# ODS5010 register map
Vendor: OCS; Series: ODS5010; File version: 1.0
CPU: CM0plus r0p0, little endian, MPU, FPU, 4 interrupt priority bits
Registers are 32-bit, read-write, reset 0x0 unless marked. A register's access mark holds for its fields unless they carry their own. Offsets are from the block's base; [hi:lo] are bit positions; {n}, {i} and the like mark numbered series.

## FLASH — Flash Memory Controller Peripheral
Base 0x40022000; register names take the prefix FLASH_
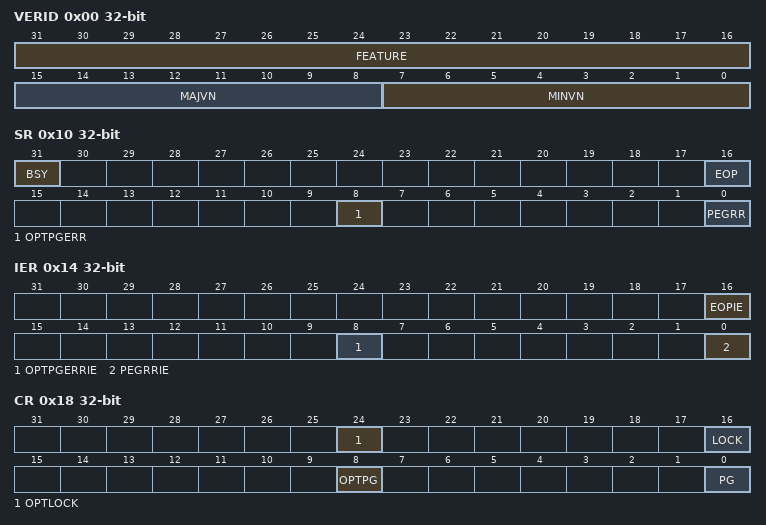
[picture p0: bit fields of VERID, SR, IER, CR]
0x00 VERID ro — Version ID Register (read only)
  [31:16] FEATURE — Feature Identification
  [15:8] MAJVN — Major Version Number
  [7:0] MINVN — Minor Version Number
0x04 ACR — Access Control Register
  [2:0] NWS — Number of Wait States
0x08 KEYR wo — Key Register (write only)
0x0C OPTKEYR wo — Option Key Register (write only)
0x10 SR ro — Status Register
  [31] BSY — Busy
  [16] EOP — End of Operation
  [8] OPTPGERR — Option Program Error
  [0] PEGRR — Program/Erase Global Result Ready
0x14 IER — Interrupt Enable Register
  [16] EOPIE — EOP Interrupt Enable
  [8] OPTPGERRIE — OPTPGERR Interrupt Enable
  [0] PEGRRIE — PEGRR Interrupt Enable
0x18 CR — Control Register
  [24] OPTLOCK — Option Lock
  [16] LOCK — Flash Lock
  [8] OPTPG — Option Program Enable
  [0] PG — Program Enable
0x24 DR ro — Data Register (read only)
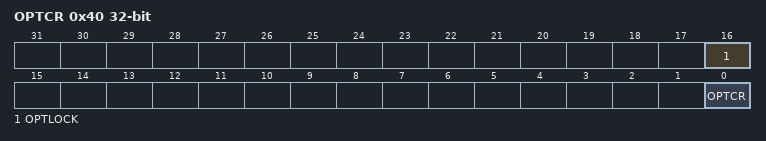
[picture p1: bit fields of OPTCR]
0x40 OPTCR — OTP Control Register
  [16] OPTLOCK — OTP Lock
  [0] OPTCR — OTP Control Bit
0x44 OPTAR — OTP Address Register
  [6:0] OPTAR — OTP Address
0x48 OPTDR — OTP Data Register
0x4C OPTKEY wo — OTP Key Register (write only)

## SYSCFG — System Configuration (SYSCFG) Peripheral
Base 0x40020400; register names take the prefix SYSCFG_
{0x0+4i} UUID{i} ro (i=0..3) — UUID Register {i}
  [31:0] UUID{i} — UUID Value {i}
{0x10+4i} USER{i} ro (i=0..3) — User Configuration Register {i}
  [31:0] USER{i} — User Configuration Value {i}
0x20 TAG ro
  [31:0] TAG — Tag Value
0x24 FLASH_SIZE ro — Flash Memory Size Register
  [31:0] FLASH_SIZE — Flash Memory Size Value
0x28 SRAM_SIZE ro
  [31:0] SRAM_SIZE — SRAM Size Value
0x2C GPIOA ro — Reserved - GPIOA Configuration
  [31:0] GPIOA — Reserved GPIOA Value
0x30 GPIOB ro — Reserved - GPIOB Configuration
  [31:0] GPIOB — Reserved GPIOB Value
0x34 GPIOC ro — Reserved - GPIOC Configuration
  [31:0] GPIOC — Reserved GPIOC Value
0x100 WAKEIR — Wake-Up Interrupt Register
  [31:0] WAKEIR — Wake-Up Interrupt Value
0x104 WAKECR — Wake-Up Control Register
  [31:0] WAKECR — Wake-Up Control Value
0x108 LPTMRTH — Low-Power Timer Threshold Register
  [31:0] LPTMRTH — Low-Power Timer Threshold Value
0x3F8 VERID ro — Version ID Register
  [31:0] VERID — Version ID Value

## MISC — MISC Control Registers (CSA and Temperature Sensor)
Base 0x40007800; register names take the prefix MISC_
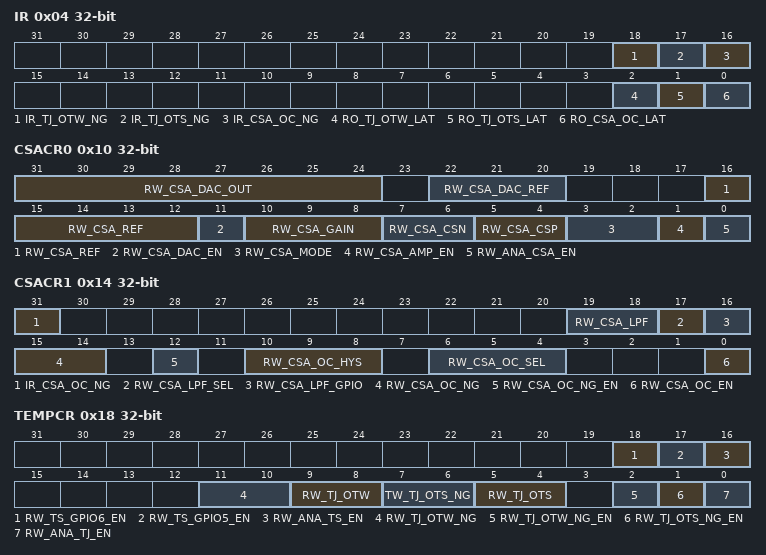
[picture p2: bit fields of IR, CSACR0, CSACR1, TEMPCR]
0x04 IR ro — MISC Interrupt Register
  [18] IR_TJ_OTW_NG — OTW over-temperature warning real-time index signal
  [17] IR_TJ_OTS_NG — OTS over-temperature shutdown real-time index signal
  [16] IR_CSA_OC_NG — CSA over-current real-time index signal
  [2] RO_TJ_OTW_LAT — Over-temperature warning (OTW) latch flag
  [1] RO_TJ_OTS_LAT — Over-temperature shutdown (OTS) latch flag
  [0] RO_CSA_OC_LAT — CSA over-current latch flag
0x10 CSACR0 — MISC CSA Control Register 0
  [31:24] RW_CSA_DAC_OUT — DAC input signal
  [22:20] RW_CSA_DAC_REF — DAC range configuration
  [16:12] RW_CSA_REF — CSA offset voltage configuration
  [11] RW_CSA_DAC_EN — DAC enable
  [10:8] RW_CSA_GAIN — CSA gain configuration
  [7:6] RW_CSA_CSN — Inverting sampling point channel selection
  [5:4] RW_CSA_CSP — Non-inverting sampling point channel selection
  [3:2] RW_CSA_MODE — CSA and ADC MUX linkage mode
  [1] RW_CSA_AMP_EN — CSA operational amplifier enable
  [0] RW_ANA_CSA_EN — CSA current sampling module enable
0x14 CSACR1 — MISC CSA Control Register 1
  [31] IR_CSA_OC_NG ro — CSA over-current real-time index signal
  [19:18] RW_CSA_LPF — CSA output filter cut-off frequency
  [17] RW_CSA_LPF_SEL — CSA output off-chip filter enable
  [16] RW_CSA_LPF_GPIO — CSA LPF external filter capacitor path enable
  [15:14] RW_CSA_OC_NG — Over-current indication signal debounce time
  [12] RW_CSA_OC_NG_EN — Over-current indication signal debounce enable
  [10:8] RW_CSA_OC_HYS — Over-current detection hysteresis configuration
  [6:4] RW_CSA_OC_SEL — Over-current detection signal selection
  [0] RW_CSA_OC_EN — CSA over-current detection enable
0x18 TEMPCR — MISC Temperature Sensor Control Register
  [18] RW_TS_GPIO6_EN — TS current output to GPIO6 enable (NTC)
  [17] RW_TS_GPIO5_EN — TS current output to GPIO5 enable (NTC)
  [16] RW_ANA_TS_EN — External temperature detection module enable
  [11:10] RW_TJ_OTW_NG — Over-temperature warning signal debounce time
  [9:8] RW_TJ_OTW — Over-temperature warning trigger temperature configuration
  [7:6] TW_TJ_OTS_NG — Over-temperature shutdown signal debounce time
  [5:4] RW_TJ_OTS — Over-temperature shutdown trigger temperature configuration
  [2] RW_TJ_OTW_NG_EN — Over-temperature warning signal debounce enable
  [1] RW_TJ_OTS_NG_EN — Over-temperature shutdown signal debounce enable
  [0] RW_ANA_TJ_EN — Internal temperature detection module enable
